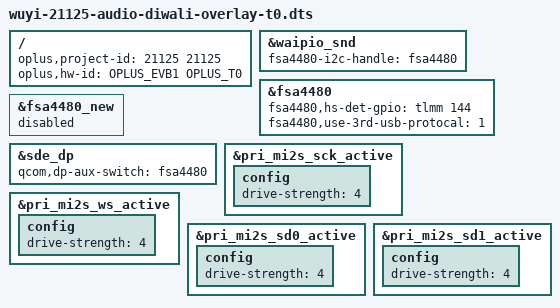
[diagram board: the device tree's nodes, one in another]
/dts-v1/;
/plugin/;
#include <dt-bindings/oplus/hw-id.h>
#include "../diwali-audio-idp.dts"
#include "diwali_audio_overlay_common.dtsi"
/ {
    oplus,project-id = <21125 21125>;
    oplus,hw-id = <OPLUS_EVB1 OPLUS_T0>;
};

&waipio_snd {
	fsa4480-i2c-handle = <&fsa4480>;
};

&fsa4480 {
	fsa4480,hs-det-gpio = <&tlmm 144 0x00>;
	fsa4480,use-3rd-usb-protocal = <1>;
	status = "okay";
};

&fsa4480_new {
	status = "disabled";
};

&sde_dp {
	qcom,dp-aux-switch = <&fsa4480>;
};

&pri_mi2s_sck_active {
	config {
		drive-strength = <4>;   /* 4 mA */
	};
};

&pri_mi2s_ws_active {
	config {
		drive-strength = <4>;   /* 4 mA */
	};
};

&pri_mi2s_sd0_active {
	config {
		drive-strength = <4>;   /* 4 mA */
	};
};

&pri_mi2s_sd1_active {
	config {
		drive-strength = <4>;   /* 4 mA */
	};
};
